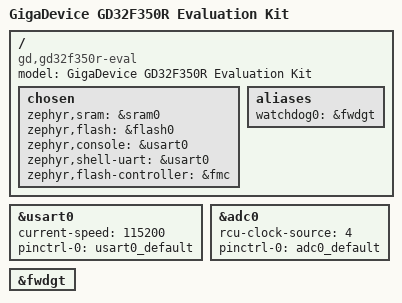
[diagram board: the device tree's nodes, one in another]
/*
 * Copyright (c) 2021 BrainCo Inc.
 * SPDX-License-Identifier: Apache-2.0
 */

/dts-v1/;

#include <gd/gd32f3x0/gd32f350rb.dtsi>
#include "gd32f350r_eval-pinctrl.dtsi"

/ {
	compatible = "gd,gd32f350r-eval";
	model = "GigaDevice GD32F350R Evaluation Kit";

	chosen {
		zephyr,sram = &sram0;
		zephyr,flash = &flash0;
		zephyr,console = &usart0;
		zephyr,shell-uart = &usart0;
		zephyr,flash-controller = &fmc;
	};

	aliases {
		watchdog0 = &fwdgt;
	};
};

&usart0 {
	current-speed = <115200>;
	pinctrl-0 = <&usart0_default>;
	pinctrl-names = "default";
	status = "okay";
};

&adc0 {
	/* Set ADC0 clock source to RCU_ADCCK_APB2_DIV4. */
	rcu-clock-source = <4>;
	pinctrl-0 = <&adc0_default>;
	pinctrl-names = "default";
	status = "okay";
};

&fwdgt {
	status = "okay";
};
